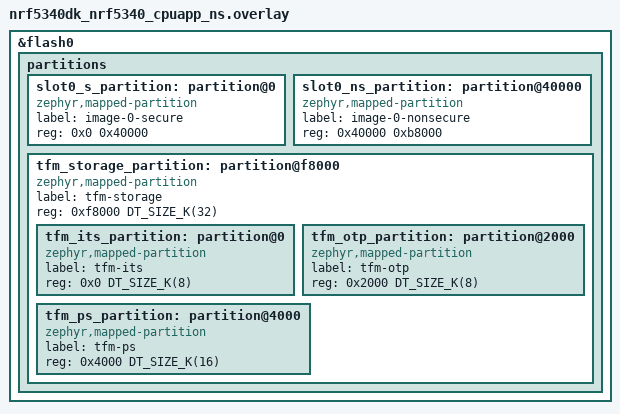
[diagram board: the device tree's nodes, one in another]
/delete-node/ &boot_partition;
/delete-node/ &slot0_partition;
/delete-node/ &slot1_partition;
/delete-node/ &storage_partition;

/delete-node/ &tfm_its_partition;
/delete-node/ &tfm_otp_partition;
/delete-node/ &tfm_ps_partition;

&flash0 {
	partitions {
		slot0_s_partition: partition@0 {
			compatible = "zephyr,mapped-partition";
			label = "image-0-secure";
			reg = <0x0 0x40000>;
		};

		slot0_ns_partition: partition@40000 {
			compatible = "zephyr,mapped-partition";
			label = "image-0-nonsecure";
			reg = <0x40000 0xb8000>;
		};

		tfm_storage_partition: partition@f8000 {
			compatible = "zephyr,mapped-partition";
			label = "tfm-storage";
			reg = <0xf8000 DT_SIZE_K(32)>;
			ranges = <0x0 0xf8000 DT_SIZE_K(32)>;
			#address-cells = <1>;
			#size-cells = <1>;

			tfm_its_partition: partition@0 {
				compatible = "zephyr,mapped-partition";
				label = "tfm-its";
				reg = <0x0 DT_SIZE_K(8)>;
			};

			tfm_otp_partition: partition@2000 {
				compatible = "zephyr,mapped-partition";
				label = "tfm-otp";
				reg = <0x2000 DT_SIZE_K(8)>;
			};

			tfm_ps_partition: partition@4000 {
				compatible = "zephyr,mapped-partition";
				label = "tfm-ps";
				reg = <0x4000 DT_SIZE_K(16)>;
			};
		};
	};
};
